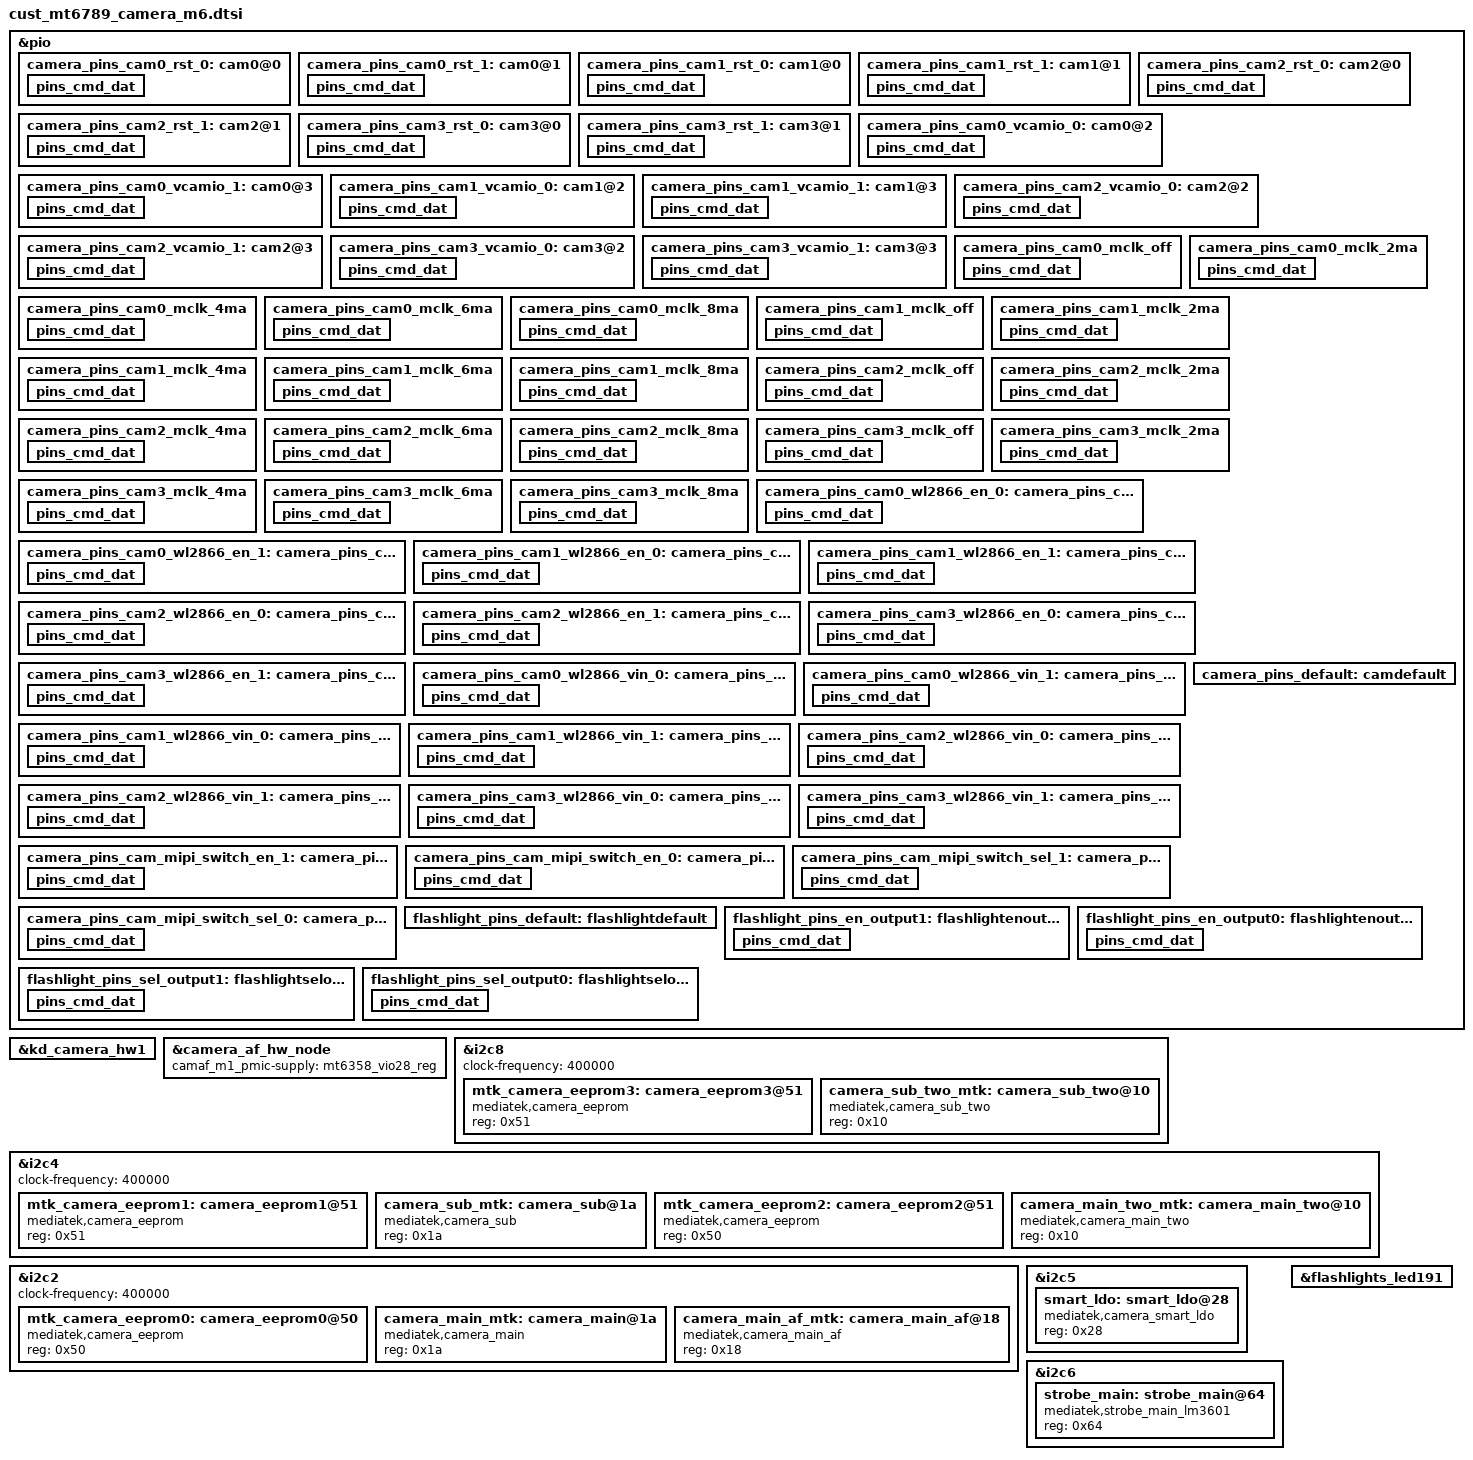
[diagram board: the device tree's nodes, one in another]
// SPDX-License-Identifier: GPL-2.0
/* Copyright (c) 2020 MediaTek Inc. */
/* CAMERA GPIO standardization */
&pio {
	camera_pins_cam0_rst_0: cam0@0 {
		pins_cmd_dat {
			pinmux = <PINMUX_GPIO20__FUNC_GPIO20>;
			slew-rate = <1>;
			output-low;
		};
	};
	camera_pins_cam0_rst_1: cam0@1 {
		pins_cmd_dat {
			pinmux = <PINMUX_GPIO20__FUNC_GPIO20>;
			slew-rate = <1>;
			output-high;
		};
	};
	camera_pins_cam1_rst_0: cam1@0 {
		pins_cmd_dat {
			pinmux = <PINMUX_GPIO16__FUNC_GPIO16>;
			slew-rate = <1>;
			output-low;
		};
	};
	camera_pins_cam1_rst_1: cam1@1 {
		pins_cmd_dat {
			pinmux = <PINMUX_GPIO16__FUNC_GPIO16>;
			slew-rate = <1>;
			output-high;
		};
	};
	camera_pins_cam2_rst_0: cam2@0 {
		pins_cmd_dat {
			pinmux = <PINMUX_GPIO22__FUNC_GPIO22>;
			slew-rate = <1>;
			output-low;
		};
	};
	camera_pins_cam2_rst_1: cam2@1 {
		pins_cmd_dat {
			pinmux = <PINMUX_GPIO22__FUNC_GPIO22>;
			slew-rate = <1>;
			output-high;
		};
	};
	camera_pins_cam3_rst_0: cam3@0 {
		pins_cmd_dat {
			pinmux = <PINMUX_GPIO18__FUNC_GPIO18>;
			slew-rate = <1>;
			output-low;
		};
	};
	camera_pins_cam3_rst_1: cam3@1 {
		pins_cmd_dat {
			pinmux = <PINMUX_GPIO18__FUNC_GPIO18>;
			slew-rate = <1>;
			output-high;
		};
	};
	camera_pins_cam0_vcamio_0: cam0@2 {
		pins_cmd_dat {
			pinmux = <PINMUX_GPIO19__FUNC_GPIO19>;
			slew-rate = <1>;
			output-low;
		};
	};
	camera_pins_cam0_vcamio_1: cam0@3 {
		pins_cmd_dat {
			pinmux = <PINMUX_GPIO19__FUNC_GPIO19>;
			slew-rate = <1>;
			output-high;
		};
	};
	camera_pins_cam1_vcamio_0: cam1@2 {
		pins_cmd_dat {
			pinmux = <PINMUX_GPIO19__FUNC_GPIO19>;
			slew-rate = <1>;
			output-low;
		};
	};
	camera_pins_cam1_vcamio_1: cam1@3 {
		pins_cmd_dat {
			pinmux = <PINMUX_GPIO19__FUNC_GPIO19>;
			slew-rate = <1>;
			output-high;
		};
	};
	camera_pins_cam2_vcamio_0: cam2@2 {
		pins_cmd_dat {
			pinmux = <PINMUX_GPIO19__FUNC_GPIO19>;
			slew-rate = <1>;
			output-low;
		};
	};
	camera_pins_cam2_vcamio_1: cam2@3 {
		pins_cmd_dat {
			pinmux = <PINMUX_GPIO19__FUNC_GPIO19>;
			slew-rate = <1>;
			output-high;
		};
	};
	camera_pins_cam3_vcamio_0: cam3@2 {
		pins_cmd_dat {
			pinmux = <PINMUX_GPIO19__FUNC_GPIO19>;
			slew-rate = <1>;
			output-low;
		};
	};
	camera_pins_cam3_vcamio_1: cam3@3 {
		pins_cmd_dat {
			pinmux = <PINMUX_GPIO19__FUNC_GPIO19>;
			slew-rate = <1>;
			output-high;
		};
	};
	camera_pins_cam0_mclk_off: camera_pins_cam0_mclk_off {
		pins_cmd_dat {
			pinmux = <PINMUX_GPIO128__FUNC_GPIO128>;
			drive-strength = <1>;
		};
	};
	camera_pins_cam0_mclk_2ma: camera_pins_cam0_mclk_2ma {
		pins_cmd_dat {
			pinmux = <PINMUX_GPIO128__FUNC_CMMCLK2>;
			drive-strength = <0>;
		};
	};
	camera_pins_cam0_mclk_4ma: camera_pins_cam0_mclk_4ma {
		pins_cmd_dat {
			pinmux = <PINMUX_GPIO128__FUNC_CMMCLK2>;
			drive-strength = <1>;
		};
	};
	camera_pins_cam0_mclk_6ma: camera_pins_cam0_mclk_6ma {
		pins_cmd_dat {
			pinmux = <PINMUX_GPIO128__FUNC_CMMCLK2>;
			drive-strength = <2>;
		};
	};
	camera_pins_cam0_mclk_8ma: camera_pins_cam0_mclk_8ma {
		pins_cmd_dat {
			pinmux = <PINMUX_GPIO128__FUNC_CMMCLK2>;
			drive-strength = <3>;
		};
	};
	camera_pins_cam1_mclk_off: camera_pins_cam1_mclk_off {
		pins_cmd_dat {
			pinmux = <PINMUX_GPIO126__FUNC_GPIO126>;
			drive-strength = <1>;
		};
	};
	camera_pins_cam1_mclk_2ma: camera_pins_cam1_mclk_2ma {
		pins_cmd_dat {
			pinmux = <PINMUX_GPIO126__FUNC_CMMCLK0>;
			drive-strength = <0>;
		};
	};
	camera_pins_cam1_mclk_4ma: camera_pins_cam1_mclk_4ma {
		pins_cmd_dat {
			pinmux = <PINMUX_GPIO126__FUNC_CMMCLK0>;
			drive-strength = <1>;
		};
	};
	camera_pins_cam1_mclk_6ma: camera_pins_cam1_mclk_6ma {
		pins_cmd_dat {
			pinmux = <PINMUX_GPIO126__FUNC_CMMCLK0>;
			drive-strength = <2>;
		};
	};
	camera_pins_cam1_mclk_8ma: camera_pins_cam1_mclk_8ma {
		pins_cmd_dat {
			pinmux = <PINMUX_GPIO126__FUNC_CMMCLK0>;
			drive-strength = <3>;
		};
	};
	camera_pins_cam2_mclk_off: camera_pins_cam2_mclk_off {
		pins_cmd_dat {
			pinmux = <PINMUX_GPIO129__FUNC_GPIO129>;
			drive-strength = <1>;
		};
	};
	camera_pins_cam2_mclk_2ma: camera_pins_cam2_mclk_2ma {
		pins_cmd_dat {
			pinmux = <PINMUX_GPIO129__FUNC_CMMCLK3>;
			drive-strength = <0>;
		};
	};
	camera_pins_cam2_mclk_4ma: camera_pins_cam2_mclk_4ma {
		pins_cmd_dat {
			pinmux = <PINMUX_GPIO129__FUNC_CMMCLK3>;
			drive-strength = <1>;
		};
	};
	camera_pins_cam2_mclk_6ma: camera_pins_cam2_mclk_6ma {
		pins_cmd_dat {
			pinmux = <PINMUX_GPIO129__FUNC_CMMCLK3>;
			drive-strength = <2>;
		};
	};
	camera_pins_cam2_mclk_8ma: camera_pins_cam2_mclk_8ma {
		pins_cmd_dat {
			pinmux = <PINMUX_GPIO129__FUNC_CMMCLK3>;
			drive-strength = <3>;
		};
	};
    camera_pins_cam3_mclk_off: camera_pins_cam3_mclk_off {
		pins_cmd_dat {
			pinmux = <PINMUX_GPIO127__FUNC_GPIO127>;
			drive-strength = <1>;
		};
	};
	camera_pins_cam3_mclk_2ma: camera_pins_cam3_mclk_2ma {
		pins_cmd_dat {
			pinmux = <PINMUX_GPIO127__FUNC_CMMCLK1>;
			drive-strength = <0>;
		};
	};
	camera_pins_cam3_mclk_4ma: camera_pins_cam3_mclk_4ma {
		pins_cmd_dat {
			pinmux = <PINMUX_GPIO127__FUNC_CMMCLK1>;
			drive-strength = <1>;
		};
	};
	camera_pins_cam3_mclk_6ma: camera_pins_cam3_mclk_6ma {
		pins_cmd_dat {
			pinmux = <PINMUX_GPIO127__FUNC_CMMCLK1>;
			drive-strength = <2>;
		};
	};
	camera_pins_cam3_mclk_8ma: camera_pins_cam3_mclk_8ma {
		pins_cmd_dat {
			pinmux = <PINMUX_GPIO127__FUNC_CMMCLK1>;
			drive-strength = <3>;
		};
	};


	camera_pins_cam0_wl2866_en_0: camera_pins_cam0_wl2866_en_0@1 {
		pins_cmd_dat {
			pinmux = <PINMUX_GPIO151__FUNC_GPIO151>;
			slew-rate = <1>;
			output-low;
		};
	};
	camera_pins_cam0_wl2866_en_1: camera_pins_cam0_wl2866_en_1@2 {
		pins_cmd_dat {
			pinmux = <PINMUX_GPIO151__FUNC_GPIO151>;
			slew-rate = <1>;
			output-high;
		};
	};
	camera_pins_cam1_wl2866_en_0: camera_pins_cam1_wl2866_en_0@3 {
		pins_cmd_dat {
			pinmux = <PINMUX_GPIO151__FUNC_GPIO151>;
			slew-rate = <1>;
			output-low;
		};
	};
	camera_pins_cam1_wl2866_en_1: camera_pins_cam1_wl2866_en_1@4 {
		pins_cmd_dat {
			pinmux = <PINMUX_GPIO151__FUNC_GPIO151>;
			slew-rate = <1>;
			output-high;
		};
	};
	camera_pins_cam2_wl2866_en_0: camera_pins_cam2_wl2866_en_0@5 {
		pins_cmd_dat {
			pinmux = <PINMUX_GPIO151__FUNC_GPIO151>;
			slew-rate = <1>;
			output-low;
		};
	};
	camera_pins_cam2_wl2866_en_1: camera_pins_cam2_wl2866_en_1@6 {
		pins_cmd_dat {
			pinmux = <PINMUX_GPIO151__FUNC_GPIO151>;
			slew-rate = <1>;
			output-high;
		};
	};

	camera_pins_cam3_wl2866_en_0: camera_pins_cam3_wl2866_en_0@7 {
		pins_cmd_dat {
			pinmux = <PINMUX_GPIO151__FUNC_GPIO151>;
			slew-rate = <1>;
			output-low;
		};
	};
	camera_pins_cam3_wl2866_en_1: camera_pins_cam3_wl2866_en_1@8 {
		pins_cmd_dat {
			pinmux = <PINMUX_GPIO151__FUNC_GPIO151>;
			slew-rate = <1>;
			output-high;
		};
	};

	camera_pins_cam0_wl2866_vin_0: camera_pins_cam0_wl2866_vin_0@1 {
		pins_cmd_dat {
			pinmux = <PINMUX_GPIO21__FUNC_GPIO21>;
			slew-rate = <1>;
			output-low;
		};
	};
	camera_pins_cam0_wl2866_vin_1: camera_pins_cam0_wl2866_vin_1@2 {
		pins_cmd_dat {
			pinmux = <PINMUX_GPIO21__FUNC_GPIO21>;
			slew-rate = <1>;
			output-high;
		};
	};
	camera_pins_cam1_wl2866_vin_0: camera_pins_cam1_wl2866_vin_0@3 {
		pins_cmd_dat {
			pinmux = <PINMUX_GPIO21__FUNC_GPIO21>;
			slew-rate = <1>;
			output-low;
		};
	};
	camera_pins_cam1_wl2866_vin_1: camera_pins_cam1_wl2866_vin_1@4 {
		pins_cmd_dat {
			pinmux = <PINMUX_GPIO21__FUNC_GPIO21>;
			slew-rate = <1>;
			output-high;
		};
	};
	camera_pins_cam2_wl2866_vin_0: camera_pins_cam2_wl2866_vin_0@5 {
		pins_cmd_dat {
			pinmux = <PINMUX_GPIO21__FUNC_GPIO21>;
			slew-rate = <1>;
			output-low;
		};
	};
	camera_pins_cam2_wl2866_vin_1: camera_pins_cam2_wl2866_vin_1@6 {
		pins_cmd_dat {
			pinmux = <PINMUX_GPIO21__FUNC_GPIO21>;
			slew-rate = <1>;
			output-high;
		};
	};

	camera_pins_cam3_wl2866_vin_0: camera_pins_cam3_wl2866_vin_0@7 {
		pins_cmd_dat {
			pinmux = <PINMUX_GPIO21__FUNC_GPIO21>;
			slew-rate = <1>;
			output-low;
		};
	};
	camera_pins_cam3_wl2866_vin_1: camera_pins_cam3_wl2866_vin_1@8 {
		pins_cmd_dat {
			pinmux = <PINMUX_GPIO21__FUNC_GPIO21>;
			slew-rate = <1>;
			output-high;
		};
	};
	camera_pins_cam_mipi_switch_en_1: camera_pins_cam_mipi_switch_en_cam2@1 {
		pins_cmd_dat {
			pinmux = <PINMUX_GPIO104__FUNC_GPIO104>;
			slew-rate = <1>;
			output-high;
		};
	};
	camera_pins_cam_mipi_switch_en_0: camera_pins_cam_mipi_switch_en_cam1@0 {
		pins_cmd_dat {
			pinmux = <PINMUX_GPIO104__FUNC_GPIO104>;
			slew-rate = <1>;
			output-low;
		};
	};
	camera_pins_cam_mipi_switch_sel_1: camera_pins_cam_mipi_switch_sel_cam2@1 {
		pins_cmd_dat {
			pinmux = <PINMUX_GPIO107__FUNC_GPIO107>;
			slew-rate = <1>;
			output-high;
		};
	};
	camera_pins_cam_mipi_switch_sel_0: camera_pins_cam_mipi_switch_sel_cam1@0 {
		pins_cmd_dat {
			pinmux = <PINMUX_GPIO107__FUNC_GPIO107>;
			slew-rate = <1>;
			output-low;
		};
	};

	camera_pins_default: camdefault {
	};
};
&kd_camera_hw1 {
	pinctrl-names = "default",
		"cam0_rst0", "cam0_rst1",
		"cam1_rst0", "cam1_rst1",
		"cam2_rst0", "cam2_rst1",
		"cam3_rst0", "cam3_rst1",
		"cam0_ldo_vcamio_0","cam0_ldo_vcamio_1",
		"cam1_ldo_vcamio_0","cam1_ldo_vcamio_1",
		"cam2_ldo_vcamio_0","cam2_ldo_vcamio_1",
		"cam3_ldo_vcamio_0","cam3_ldo_vcamio_1",
		"cam0_mclk_off",
		"cam0_mclk_2mA", "cam0_mclk_4mA",
		"cam0_mclk_6mA", "cam0_mclk_8mA",
		"cam1_mclk_off",
		"cam1_mclk_2mA", "cam1_mclk_4mA",
		"cam1_mclk_6mA", "cam1_mclk_8mA",
		"cam2_mclk_off",
		"cam2_mclk_2mA", "cam2_mclk_4mA",
		"cam2_mclk_6mA", "cam2_mclk_8mA",
		"cam3_mclk_off",
		"cam3_mclk_2mA", "cam3_mclk_4mA",
		"cam3_mclk_6mA", "cam3_mclk_8mA",
		"cam0_ldo_wl2866d_en_0","cam0_ldo_wl2866d_en_1",
		"cam0_ldo_wl2866d_vin_0","cam0_ldo_wl2866d_vin_1",
		"cam1_ldo_wl2866d_en_0","cam1_ldo_wl2866d_en_1",
		"cam1_ldo_wl2866d_vin_0","cam1_ldo_wl2866d_vin_1",
		"cam2_ldo_wl2866d_en_0","cam2_ldo_wl2866d_en_1",
		"cam2_ldo_wl2866d_vin_0","cam2_ldo_wl2866d_vin_1",
		"cam3_ldo_wl2866d_en_0","cam3_ldo_wl2866d_en_1",
		"cam3_ldo_wl2866d_vin_0","cam3_ldo_wl2866d_vin_1",
		"cam_mipi_switch_en_1", "cam_mipi_switch_en_0",
		"cam_mipi_switch_sel_1", "cam_mipi_switch_sel_0";


	pinctrl-0 = <&camera_pins_default>;
	pinctrl-1 = <&camera_pins_cam0_rst_0>;
	pinctrl-2 = <&camera_pins_cam0_rst_1>;
	pinctrl-3 = <&camera_pins_cam1_rst_0>;
	pinctrl-4 = <&camera_pins_cam1_rst_1>;
	pinctrl-5 = <&camera_pins_cam2_rst_0>;
	pinctrl-6 = <&camera_pins_cam2_rst_1>;
	pinctrl-7 = <&camera_pins_cam3_rst_0>;
	pinctrl-8 = <&camera_pins_cam3_rst_1>;

	pinctrl-9 = <&camera_pins_cam0_vcamio_0>;
	pinctrl-10 = <&camera_pins_cam0_vcamio_1>;
	pinctrl-11 = <&camera_pins_cam1_vcamio_0>;
	pinctrl-12 = <&camera_pins_cam1_vcamio_1>;
	pinctrl-13 = <&camera_pins_cam2_vcamio_0>;
	pinctrl-14 = <&camera_pins_cam2_vcamio_1>;
	pinctrl-15 = <&camera_pins_cam3_vcamio_0>;
	pinctrl-16 = <&camera_pins_cam3_vcamio_1>;

	pinctrl-17 = <&camera_pins_cam0_mclk_off>;
	pinctrl-18 = <&camera_pins_cam0_mclk_2ma>;
	pinctrl-19 = <&camera_pins_cam0_mclk_4ma>;
	pinctrl-20 = <&camera_pins_cam0_mclk_6ma>;
	pinctrl-21 = <&camera_pins_cam0_mclk_8ma>;
	pinctrl-22 = <&camera_pins_cam1_mclk_off>;
	pinctrl-23 = <&camera_pins_cam1_mclk_2ma>;
	pinctrl-24 = <&camera_pins_cam1_mclk_4ma>;
	pinctrl-25 = <&camera_pins_cam1_mclk_6ma>;
	pinctrl-26 = <&camera_pins_cam1_mclk_8ma>;
	pinctrl-27 = <&camera_pins_cam2_mclk_off>;
	pinctrl-28 = <&camera_pins_cam2_mclk_2ma>;
	pinctrl-29 = <&camera_pins_cam2_mclk_4ma>;
	pinctrl-30 = <&camera_pins_cam2_mclk_6ma>;
	pinctrl-31 = <&camera_pins_cam2_mclk_8ma>;
	pinctrl-32 = <&camera_pins_cam3_mclk_off>;
	pinctrl-33 = <&camera_pins_cam3_mclk_2ma>;
	pinctrl-34 = <&camera_pins_cam3_mclk_4ma>;
	pinctrl-35 = <&camera_pins_cam3_mclk_6ma>;
	pinctrl-36 = <&camera_pins_cam3_mclk_8ma>;

	pinctrl-37 = <&camera_pins_cam0_wl2866_en_0>;
	pinctrl-38 = <&camera_pins_cam0_wl2866_en_1>;
	pinctrl-39 = <&camera_pins_cam1_wl2866_en_0>;
	pinctrl-40 = <&camera_pins_cam1_wl2866_en_1>;
	pinctrl-41 = <&camera_pins_cam2_wl2866_en_0>;
	pinctrl-42 = <&camera_pins_cam2_wl2866_en_1>;
	pinctrl-43 = <&camera_pins_cam3_wl2866_en_0>;
	pinctrl-44 = <&camera_pins_cam3_wl2866_en_1>;
	pinctrl-45 = <&camera_pins_cam0_wl2866_vin_0>;
	pinctrl-46 = <&camera_pins_cam0_wl2866_vin_1>;
	pinctrl-47 = <&camera_pins_cam1_wl2866_vin_0>;
	pinctrl-48 = <&camera_pins_cam1_wl2866_vin_1>;
	pinctrl-49 = <&camera_pins_cam2_wl2866_vin_0>;
	pinctrl-50 = <&camera_pins_cam2_wl2866_vin_1>;
	pinctrl-51 = <&camera_pins_cam3_wl2866_vin_0>;
	pinctrl-52 = <&camera_pins_cam3_wl2866_vin_1>;
	pinctrl-53 = <&camera_pins_cam_mipi_switch_en_1>;
	pinctrl-54 = <&camera_pins_cam_mipi_switch_en_0>;
	pinctrl-55 = <&camera_pins_cam_mipi_switch_sel_1>;
	pinctrl-56 = <&camera_pins_cam_mipi_switch_sel_0>;
	status = "okay";
	cam0_enable_sensor = "s5khm2sp_mipi_raw s5khm2sd_mipi_raw";
	cam1_enable_sensor = "ov16a1qsunny_mipi_raw ov16a1qaac_mipi_raw";
	cam2_enable_sensor = "imx355ofilm_mipi_raw imx355aac_mipi_raw";
	cam3_enable_sensor = "ov02b10_mipi_raw sc202cs_sunny_mipi_raw";
};
/* CAMERA GPIO end */

/* main af */
&camera_af_hw_node {
    camaf_m1_pmic-supply = <&mt6358_vio28_reg>;
};
/* CAMERA EEPROM */
&i2c8 {
	status = "okay";
	clock-frequency = <400000>;
	#address-cells = <1>;
	#size-cells = <0>;

	mtk_camera_eeprom3:camera_eeprom3@51 {
		compatible = "mediatek,camera_eeprom";
		reg = <0x51>;
		status = "okay";
	};
	camera_sub_two_mtk:camera_sub_two@10 {
		compatible = "mediatek,camera_sub_two";
		#thermal-sensor-cells = <0>;
		reg = <0x10>;
		status = "okay";
	};
};
&i2c4 {
	status = "okay";
	clock-frequency = <400000>;
	#address-cells = <1>;
	#size-cells = <0>;

	mtk_camera_eeprom1:camera_eeprom1@51 {
		compatible = "mediatek,camera_eeprom";
		reg = <0x51>;
		status = "okay";
	};
	camera_sub_mtk:camera_sub@1a {
		compatible = "mediatek,camera_sub";
		#thermal-sensor-cells = <0>;
		reg = <0x1a>;
		status = "okay";
	};
};
&i2c2 {
	status = "okay";
	clock-frequency = <400000>;
	#address-cells = <1>;
	#size-cells = <0>;

	mtk_camera_eeprom0:camera_eeprom0@50 {
		compatible = "mediatek,camera_eeprom";
		reg = <0x50>;
		status = "okay";
	};
	camera_main_mtk:camera_main@1a {
		compatible = "mediatek,camera_main";
		#thermal-sensor-cells = <0>;
		reg = <0x1a>;
		status = "okay";
	};
	camera_main_af_mtk:camera_main_af@18 {
		compatible = "mediatek,camera_main_af";
		reg = <0x18>;
		status = "okay";
	};
};
&i2c4 {
	status = "okay";
	clock-frequency = <400000>;
	#address-cells = <1>;
	#size-cells = <0>;

	mtk_camera_eeprom2:camera_eeprom2@51 {
		compatible = "mediatek,camera_eeprom";
		reg = <0x50>;
		status = "okay";
	};
	camera_main_two_mtk:camera_main_two@10 {
		compatible = "mediatek,camera_main_two";
		#thermal-sensor-cells = <0>;
		reg = <0x10>;
		status = "okay";
	};
};
/* CAMERA EEPROM end */

/* CAMERA SMART LDO */
&i2c5 {
    smart_ldo:smart_ldo@28 {
        compatible = "mediatek,camera_smart_ldo";
		reg = <0x28>;
		status = "okay";
	};
};
/* CAMERA SMART LDO  end */

/*M6 ADD CAMERA FLASHLIGHT*/
&i2c6 {
	strobe_main:strobe_main@64 {
		compatible = "mediatek,strobe_main_lm3601";
		reg = <0x64>;
		status = "okay";
	};
};
/*M6 ADD CAMERA FLASHLIGHT END*/

/* CAMERA FLASHLIGHT */
&flashlights_led191 {
		pinctrl-names = "default", "hw_ch0_high",
				"hw_ch0_low", "hw_ch1_high",
				"hw_ch1_low";
		pinctrl-0 = <&flashlight_pins_default>;
		pinctrl-1 = <&flashlight_pins_en_output1>;
		pinctrl-2 = <&flashlight_pins_en_output0>;
		pinctrl-3 = <&flashlight_pins_sel_output1>;
		pinctrl-4 = <&flashlight_pins_sel_output0>;
		status = "okay";
};
&pio {
		flashlight_pins_default: flashlightdefault {
		};
		flashlight_pins_en_output1: flashlightenoutput1 {
				pins_cmd_dat {
						pinmux = <PINMUX_GPIO155__FUNC_GPIO155>;
						slew-rate = <1>;
						output-high;
				};
		};
		flashlight_pins_en_output0: flashlightenoutput0 {
				pins_cmd_dat {
						pinmux = <PINMUX_GPIO155__FUNC_GPIO155>;
						slew-rate = <1>;
						output-low;
				};
		};
		flashlight_pins_sel_output1: flashlightseloutput1 {
				pins_cmd_dat {
						pinmux = <PINMUX_GPIO155__FUNC_GPIO155>;
						slew-rate = <1>;
						output-high;
				};
		};
		flashlight_pins_sel_output0: flashlightseloutput0 {
					pins_cmd_dat {
						pinmux = <PINMUX_GPIO155__FUNC_GPIO155>;
						slew-rate = <1>;
						output-low;
				};
		};
};
/* CAMERA FLASHLIGHT end */
